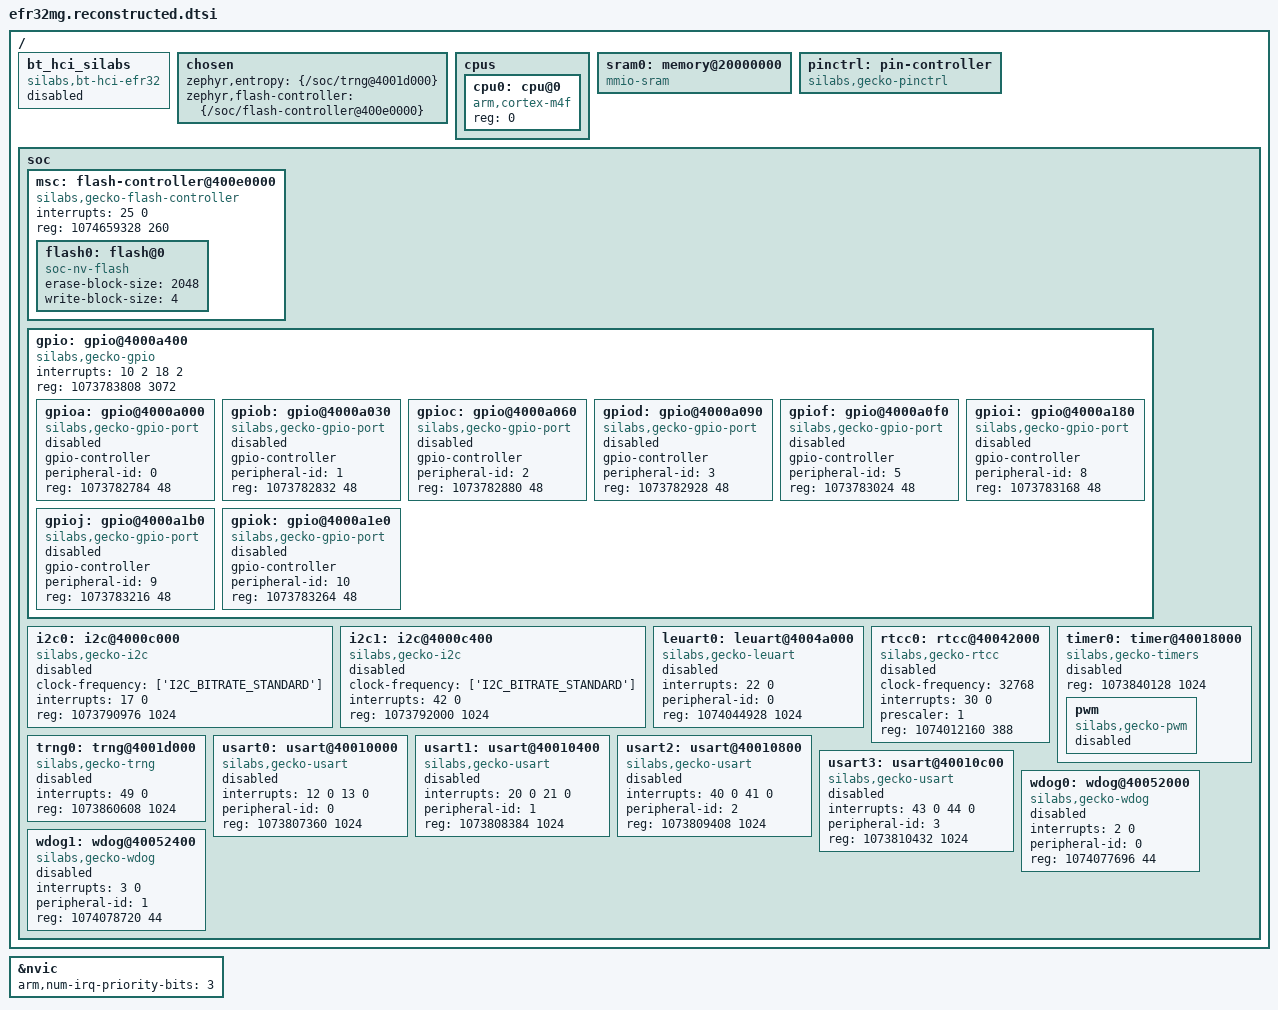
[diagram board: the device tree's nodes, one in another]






#include <arm/armv7-m.dtsi>
#include <zephyr/dt-bindings/gpio/gpio.h>
#include <zephyr/dt-bindings/i2c/i2c.h>
#include "gpio_gecko.h"
#include <zephyr/dt-bindings/pwm/pwm.h>

/ {
    bt_hci_silabs: bt_hci_silabs {
        compatible = "silabs,bt-hci-efr32";

        status = "disabled";

    };

    chosen {
        zephyr,entropy = <&{/soc/trng@4001d000}>;

        zephyr,flash-controller = <&{/soc/flash-controller@400e0000}>;

    };

    cpus {
        #address-cells = <1>;

        #size-cells = <0>;

        cpu0: cpu@0 {
            compatible = "arm,cortex-m4f";

            reg = <0>;

        };

    };

    sram0: memory@20000000 {
        compatible = "mmio-sram";

    };

    pinctrl: pin-controller {
        compatible = "silabs,gecko-pinctrl";

    };

    soc {
        msc: flash-controller@400e0000 {
            #address-cells = <1>;

            #size-cells = <1>;

            compatible = "silabs,gecko-flash-controller";

            interrupts = <25 0>;

            reg = <1074659328 260>;

            flash0: flash@0 {
                compatible = "soc-nv-flash";

                erase-block-size = <2048>;

                write-block-size = <4>;

            };

        };

        gpio: gpio@4000a400 {
            #address-cells = <1>;

            #size-cells = <1>;

            compatible = "silabs,gecko-gpio";

            interrupt-names = "GPIO_EVEN", "GPIO_ODD";

            interrupts = <10 2 18 2>;

            ranges;

            reg = <1073783808 3072>;

            gpioa: gpio@4000a000 {
                #gpio-cells = <2>;

                compatible = "silabs,gecko-gpio-port";

                gpio-controller;

                peripheral-id = <0>;

                reg = <1073782784 48>;

                status = "disabled";

            };

            gpiob: gpio@4000a030 {
                #gpio-cells = <2>;

                compatible = "silabs,gecko-gpio-port";

                gpio-controller;

                peripheral-id = <1>;

                reg = <1073782832 48>;

                status = "disabled";

            };

            gpioc: gpio@4000a060 {
                #gpio-cells = <2>;

                compatible = "silabs,gecko-gpio-port";

                gpio-controller;

                peripheral-id = <2>;

                reg = <1073782880 48>;

                status = "disabled";

            };

            gpiod: gpio@4000a090 {
                #gpio-cells = <2>;

                compatible = "silabs,gecko-gpio-port";

                gpio-controller;

                peripheral-id = <3>;

                reg = <1073782928 48>;

                status = "disabled";

            };

            gpiof: gpio@4000a0f0 {
                #gpio-cells = <2>;

                compatible = "silabs,gecko-gpio-port";

                gpio-controller;

                peripheral-id = <5>;

                reg = <1073783024 48>;

                status = "disabled";

            };

            gpioi: gpio@4000a180 {
                #gpio-cells = <2>;

                compatible = "silabs,gecko-gpio-port";

                gpio-controller;

                peripheral-id = <8>;

                reg = <1073783168 48>;

                status = "disabled";

            };

            gpioj: gpio@4000a1b0 {
                #gpio-cells = <2>;

                compatible = "silabs,gecko-gpio-port";

                gpio-controller;

                peripheral-id = <9>;

                reg = <1073783216 48>;

                status = "disabled";

            };

            gpiok: gpio@4000a1e0 {
                #gpio-cells = <2>;

                compatible = "silabs,gecko-gpio-port";

                gpio-controller;

                peripheral-id = <10>;

                reg = <1073783264 48>;

                status = "disabled";

            };

        };

        i2c0: i2c@4000c000 {
            #address-cells = <1>;

            #size-cells = <0>;

            clock-frequency = <['I2C_BITRATE_STANDARD']>;

            compatible = "silabs,gecko-i2c";

            interrupts = <17 0>;

            reg = <1073790976 1024>;

            status = "disabled";

        };

        i2c1: i2c@4000c400 {
            #address-cells = <1>;

            #size-cells = <0>;

            clock-frequency = <['I2C_BITRATE_STANDARD']>;

            compatible = "silabs,gecko-i2c";

            interrupts = <42 0>;

            reg = <1073792000 1024>;

            status = "disabled";

        };

        leuart0: leuart@4004a000 {
            compatible = "silabs,gecko-leuart";

            interrupts = <22 0>;

            peripheral-id = <0>;

            reg = <1074044928 1024>;

            status = "disabled";

        };

        rtcc0: rtcc@40042000 {
            clock-frequency = <32768>;

            compatible = "silabs,gecko-rtcc";

            interrupts = <30 0>;

            prescaler = <1>;

            reg = <1074012160 388>;

            status = "disabled";

        };

        timer0: timer@40018000 {
            compatible = "silabs,gecko-timers";

            reg = <1073840128 1024>;

            status = "disabled";

            pwm {
                #pwm-cells = <3>;

                compatible = "silabs,gecko-pwm";

                status = "disabled";

            };

        };

        trng0: trng@4001d000 {
            compatible = "silabs,gecko-trng";

            interrupts = <49 0>;

            reg = <1073860608 1024>;

            status = "disabled";

        };

        usart0: usart@40010000 {
            compatible = "silabs,gecko-usart";

            interrupt-names = "rx", "tx";

            interrupts = <12 0 13 0>;

            peripheral-id = <0>;

            reg = <1073807360 1024>;

            status = "disabled";

        };

        usart1: usart@40010400 {
            compatible = "silabs,gecko-usart";

            interrupt-names = "rx", "tx";

            interrupts = <20 0 21 0>;

            peripheral-id = <1>;

            reg = <1073808384 1024>;

            status = "disabled";

        };

        usart2: usart@40010800 {
            compatible = "silabs,gecko-usart";

            interrupt-names = "rx", "tx";

            interrupts = <40 0 41 0>;

            peripheral-id = <2>;

            reg = <1073809408 1024>;

            status = "disabled";

        };

        usart3: usart@40010c00 {
            compatible = "silabs,gecko-usart";

            interrupt-names = "rx", "tx";

            interrupts = <43 0 44 0>;

            peripheral-id = <3>;

            reg = <1073810432 1024>;

            status = "disabled";

        };

        wdog0: wdog@40052000 {
            compatible = "silabs,gecko-wdog";

            interrupts = <2 0>;

            peripheral-id = <0>;

            reg = <1074077696 44>;

            status = "disabled";

        };

        wdog1: wdog@40052400 {
            compatible = "silabs,gecko-wdog";

            interrupts = <3 0>;

            peripheral-id = <1>;

            reg = <1074078720 44>;

            status = "disabled";

        };

    };

};



&nvic {
    arm,num-irq-priority-bits = <3>;

};
